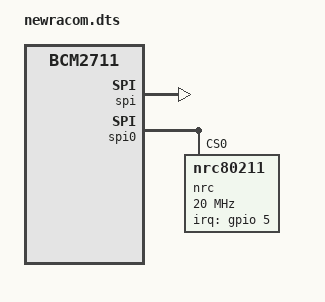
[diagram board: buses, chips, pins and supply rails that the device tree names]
/dts-v1/;
/plugin/;

/ {
    compatible = "brcm,bcm2835", "brcm,bcm2708", "brcm,bcm2709", "brcm,bcm2711";

    fragment@0 {
        target = <&spi>;
        __overlay__ {
            pinctrl-names="default";
            pinctrl-0=<&nrc_pins>;
            status = "okay";

            spidev@0 { status = "disabled"; };
            spidev@1 { status = "disabled"; };
        };
    };

    fragment@1 {
        target = <&gpio>;
        __overlay__ {
            nrc_pins: nrc_pins {
                brcm,pins = <5 7 8 9 10 11>;
                brcm,function = <0 1 1 4 4 4>;
                brcm,pull = <1 2 2 2 2 1>;
            };
        };
    };

    fragment@2 {
        target = <&spi0>;
        __overlay__ {
            pinctrl-names="default";
            pinctrl-0=<&nrc_pins>;
            status = "okay";
            #address-cells = <1>;
            #size-cells = <0>;

            nrc: nrc-cspi@0 {
                compatible = "nrc80211";
                reg = <0>;                     /* Chip Select 0 */
                interrupt-parent = <&gpio>;
                interrupts = <5 4>;            /* GPIO5, IRQ active high */
                spi-max-frequency = <20000000>;
            };
        };
    };

    __overrides__ {
        max_speed_hz = <&nrc>,"spi-max-frequency:0";
    };
};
